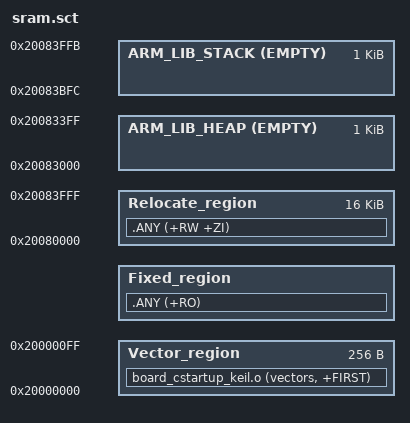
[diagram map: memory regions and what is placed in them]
; *------------------------------------------------------------------------------
; *      Linker scatter for running in internal SRAM on the AT91SAM3U4
; *----------------------------------------------------------------------------*/

Load_region 0x20000000 0x8000
{
    ; RAM0 32K
    Vector_region 0x20000000 0x100
    {
        board_cstartup_keil.o (vectors, +FIRST)
    }

    Fixed_region +0
    {
        .ANY (+RO)
    }

    ; RAM1 16K
    Relocate_region 0x20080000 0x4000
    {
        .ANY (+RW +ZI)
    }

    ; Configure Stack and Heap
    ARM_LIB_HEAP 0x20083000 EMPTY 0x400
    {
    }

    ARM_LIB_STACK 0x20083FFC EMPTY -0x400
    {
    }
}
